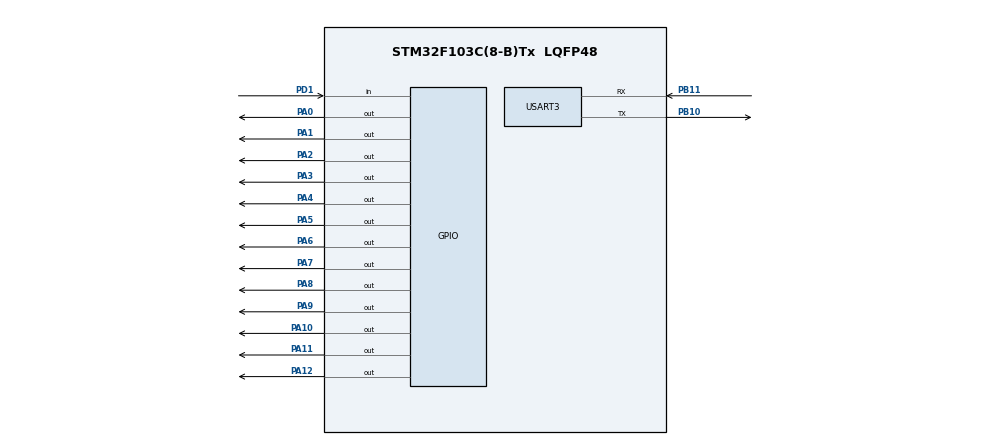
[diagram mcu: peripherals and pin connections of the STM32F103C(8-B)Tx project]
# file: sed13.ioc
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Dma.Request0=USART3_RX
Dma.USART3_RX.0.Direction=DMA_PERIPH_TO_MEMORY
Dma.USART3_RX.0.Instance=DMA1_Channel3
Dma.USART3_RX.0.MemDataAlignment=DMA_MDATAALIGN_BYTE
Dma.USART3_RX.0.MemInc=DMA_MINC_ENABLE
Dma.USART3_RX.0.Mode=DMA_CIRCULAR
Dma.USART3_RX.0.PeriphDataAlignment=DMA_PDATAALIGN_BYTE
Dma.USART3_RX.0.PeriphInc=DMA_PINC_DISABLE
Dma.USART3_RX.0.Priority=DMA_PRIORITY_LOW
Mcu.Family=STM32F1
Mcu.Name=STM32F103C(8-B)Tx
Mcu.Package=LQFP48
NVIC.DMA1_Channel3_IRQn=true\:0\:0\:false\:false\:true
NVIC.PriorityGroup=NVIC_PRIORITYGROUP_4
NVIC.USART3_IRQn=true\:0\:0\:false\:false\:true
PA0-WKUP.Signal=GPIO_Output
PA1.Signal=GPIO_Output
PA10.Signal=GPIO_Output
PA11.Signal=GPIO_Output
PA12.Signal=GPIO_Output
PA13.Mode=Serial_Wire
PA13.Signal=SYS_JTMS-SWDIO
PA14.Mode=Serial_Wire
PA14.Signal=SYS_JTCK-SWCLK
PA2.Signal=GPIO_Output
PA3.Signal=GPIO_Output
PA4.Signal=GPIO_Output
PA5.Signal=GPIO_Output
PA6.Signal=GPIO_Output
PA7.Signal=GPIO_Output
PA8.Signal=GPIO_Output
PA9.Signal=GPIO_Output
PB10.Mode=Asynchronous
PB10.Signal=USART3_TX
PB11.Mode=Asynchronous
PB11.Signal=USART3_RX
PD1-OSC_OUT.Signal=GPIO_Input
ProjectManager.HeapSize=0x200
ProjectManager.StackSize=0x400
ProjectManager.TargetToolchain=SW4STM32
RCC.APB1Freq_Value=8000000
RCC.APB2Freq_Value=8000000
USART3.VirtualMode=VM_ASYNC
board=sed13

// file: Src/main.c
/**
  ******************************************************************************
  * File Name          : main.c
  * Description        : Main program body
  ******************************************************************************
  ** This notice applies to any and all portions of this file
  * that are not between comment pairs USER CODE BEGIN and
  * USER CODE END. Other portions of this file, whether
  * inserted by the user or by software development tools
  * are owned by their respective copyright owners.
  *
  * COPYRIGHT(c) 2017 STMicroelectronics
  *
  * Redistribution and use in source and binary forms, with or without modification,
  * are permitted provided that the following conditions are met:
  *   1. Redistributions of source code must retain the above copyright notice,
  *      this list of conditions and the following disclaimer.
  *   2. Redistributions in binary form must reproduce the above copyright notice,
  *      this list of conditions and the following disclaimer in the documentation
  *      and/or other materials provided with the distribution.
  *   3. Neither the name of STMicroelectronics nor the names of its contributors
  *      may be used to endorse or promote products derived from this software
  *      without specific prior written permission.
  *
  * THIS SOFTWARE IS PROVIDED BY THE COPYRIGHT HOLDERS AND CONTRIBUTORS "AS IS"
  * AND ANY EXPRESS OR IMPLIED WARRANTIES, INCLUDING, BUT NOT LIMITED TO, THE
  * IMPLIED WARRANTIES OF MERCHANTABILITY AND FITNESS FOR A PARTICULAR PURPOSE ARE
  * DISCLAIMED. IN NO EVENT SHALL THE COPYRIGHT HOLDER OR CONTRIBUTORS BE LIABLE
  * FOR ANY DIRECT, INDIRECT, INCIDENTAL, SPECIAL, EXEMPLARY, OR CONSEQUENTIAL
  * DAMAGES (INCLUDING, BUT NOT LIMITED TO, PROCUREMENT OF SUBSTITUTE GOODS OR
  * SERVICES; LOSS OF USE, DATA, OR PROFITS; OR BUSINESS INTERRUPTION) HOWEVER
  * CAUSED AND ON ANY THEORY OF LIABILITY, WHETHER IN CONTRACT, STRICT LIABILITY,
  * OR TORT (INCLUDING NEGLIGENCE OR OTHERWISE) ARISING IN ANY WAY OUT OF THE USE
  * OF THIS SOFTWARE, EVEN IF ADVISED OF THE POSSIBILITY OF SUCH DAMAGE.
  *
  ******************************************************************************
  */
#include "main.h"
#include "stm32f1xx_hal.h"

/* USER CODE BEGIN Includes */
#include "graphic.h"
#include "sed1335.h"
#include "term.h"
/* USER CODE END Includes */

UART_HandleTypeDef huart3;
DMA_HandleTypeDef hdma_usart3_rx;

/* USER CODE BEGIN PV */
/* Private variables ---------------------------------------------------------*/

/* USER CODE END PV */

void SystemClock_Config(void);
static void MX_GPIO_Init(void);
static void MX_DMA_Init(void);
static void MX_USART3_UART_Init(void);

/* USER CODE BEGIN PFP */
/* Private function prototypes -----------------------------------------------*/

/* USER CODE END PFP */

int main(void)
{

  /* MCU Configuration----------------------------------------------------------*/

  /* Reset of all peripherals, Initializes the Flash interface and the Systick. */
  HAL_Init();

  /* Configure the system clock */
  SystemClock_Config();

  /* Initialize all configured peripherals */
  MX_GPIO_Init();
  MX_DMA_Init();
  MX_USART3_UART_Init();

  /* USER CODE BEGIN 2 */
  HAL_Delay(1000);

TermInit(&huart3);

uint8_t pos = 0;
uint8_t strnum = 0;
char c = 0;

  /* USER CODE END 2 */

  /* Infinite loop */
  /* USER CODE BEGIN WHILE */
  while (1)
  {

	  TermProc();
  /* USER CODE END WHILE */

  }

}

/** System Clock Configuration
*/
void SystemClock_Config(void)
{

  RCC_OscInitTypeDef RCC_OscInitStruct;
  RCC_ClkInitTypeDef RCC_ClkInitStruct;

    /**Initializes the CPU, AHB and APB busses clocks
    */
  RCC_OscInitStruct.OscillatorType = RCC_OSCILLATORTYPE_HSI;
  RCC_OscInitStruct.HSIState = RCC_HSI_ON;
  RCC_OscInitStruct.HSICalibrationValue = 16;
  RCC_OscInitStruct.PLL.PLLState = RCC_PLL_NONE;
  if (HAL_RCC_OscConfig(&RCC_OscInitStruct) != HAL_OK)
  {
    _Error_Handler(__FILE__, __LINE__);
  }

    /**Initializes the CPU, AHB and APB busses clocks
    */
  RCC_ClkInitStruct.ClockType = RCC_CLOCKTYPE_HCLK|RCC_CLOCKTYPE_SYSCLK
                              |RCC_CLOCKTYPE_PCLK1|RCC_CLOCKTYPE_PCLK2;
  RCC_ClkInitStruct.SYSCLKSource = RCC_SYSCLKSOURCE_HSI;
  RCC_ClkInitStruct.AHBCLKDivider = RCC_SYSCLK_DIV1;
  RCC_ClkInitStruct.APB1CLKDivider = RCC_HCLK_DIV1;
  RCC_ClkInitStruct.APB2CLKDivider = RCC_HCLK_DIV1;

  if (HAL_RCC_ClockConfig(&RCC_ClkInitStruct, FLASH_LATENCY_0) != HAL_OK)
  {
    _Error_Handler(__FILE__, __LINE__);
  }

    /**Configure the Systick interrupt time
    */
  HAL_SYSTICK_Config(HAL_RCC_GetHCLKFreq()/1000);

    /**Configure the Systick
    */
  HAL_SYSTICK_CLKSourceConfig(SYSTICK_CLKSOURCE_HCLK);

  /* SysTick_IRQn interrupt configuration */
  HAL_NVIC_SetPriority(SysTick_IRQn, 0, 0);
}

/* USART3 init function */
static void MX_USART3_UART_Init(void)
{

  huart3.Instance = USART3;
  huart3.Init.BaudRate = 115200;
  huart3.Init.WordLength = UART_WORDLENGTH_8B;
  huart3.Init.StopBits = UART_STOPBITS_1;
  huart3.Init.Parity = UART_PARITY_NONE;
  huart3.Init.Mode = UART_MODE_TX_RX;
  huart3.Init.HwFlowCtl = UART_HWCONTROL_NONE;
  huart3.Init.OverSampling = UART_OVERSAMPLING_16;
  if (HAL_UART_Init(&huart3) != HAL_OK)
  {
    _Error_Handler(__FILE__, __LINE__);
  }

}

static void MX_DMA_Init(void)
{
  /* DMA controller clock enable */
  __HAL_RCC_DMA1_CLK_ENABLE();

  /* DMA interrupt init */
  /* DMA1_Channel3_IRQn interrupt configuration */
  HAL_NVIC_SetPriority(DMA1_Channel3_IRQn, 0, 0);
  HAL_NVIC_EnableIRQ(DMA1_Channel3_IRQn);

}

/** Configure pins as
        * Analog
        * Input
        * Output
        * EVENT_OUT
        * EXTI
*/
static void MX_GPIO_Init(void)
{

  GPIO_InitTypeDef GPIO_InitStruct;

  /* GPIO Ports Clock Enable */
  __HAL_RCC_GPIOD_CLK_ENABLE();
  __HAL_RCC_GPIOA_CLK_ENABLE();
  __HAL_RCC_GPIOB_CLK_ENABLE();

  /*Configure GPIO pin Output Level */
  HAL_GPIO_WritePin(GPIOA, GPIO_PIN_0|GPIO_PIN_1|GPIO_PIN_2|GPIO_PIN_3
                          |GPIO_PIN_4|GPIO_PIN_5|GPIO_PIN_6|GPIO_PIN_7
                          |GPIO_PIN_8|GPIO_PIN_9|GPIO_PIN_10|GPIO_PIN_11
                          |GPIO_PIN_12, GPIO_PIN_RESET);

  /*Configure GPIO pin : PD1 */
  GPIO_InitStruct.Pin = GPIO_PIN_1;
  GPIO_InitStruct.Mode = GPIO_MODE_INPUT;
  GPIO_InitStruct.Pull = GPIO_NOPULL;
  HAL_GPIO_Init(GPIOD, &GPIO_InitStruct);

  /*Configure GPIO pins : PA0 PA1 PA2 PA3
                           PA4 PA5 PA6 PA7
                           PA8 PA9 PA10 PA11
                           PA12 */
  GPIO_InitStruct.Pin = GPIO_PIN_0|GPIO_PIN_1|GPIO_PIN_2|GPIO_PIN_3
                          |GPIO_PIN_4|GPIO_PIN_5|GPIO_PIN_6|GPIO_PIN_7
                          |GPIO_PIN_8|GPIO_PIN_9|GPIO_PIN_10|GPIO_PIN_11
                          |GPIO_PIN_12;
  GPIO_InitStruct.Mode = GPIO_MODE_OUTPUT_PP;
  GPIO_InitStruct.Speed = GPIO_SPEED_FREQ_LOW;
  HAL_GPIO_Init(GPIOA, &GPIO_InitStruct);

  /*Configure peripheral I/O remapping */
  __HAL_AFIO_REMAP_PD01_ENABLE();

}

void _Error_Handler(char * file, int line)
{
  while(1)
  {
  }
}

/************************ (C) COPYRIGHT STMicroelectronics *****END OF FILE****/
